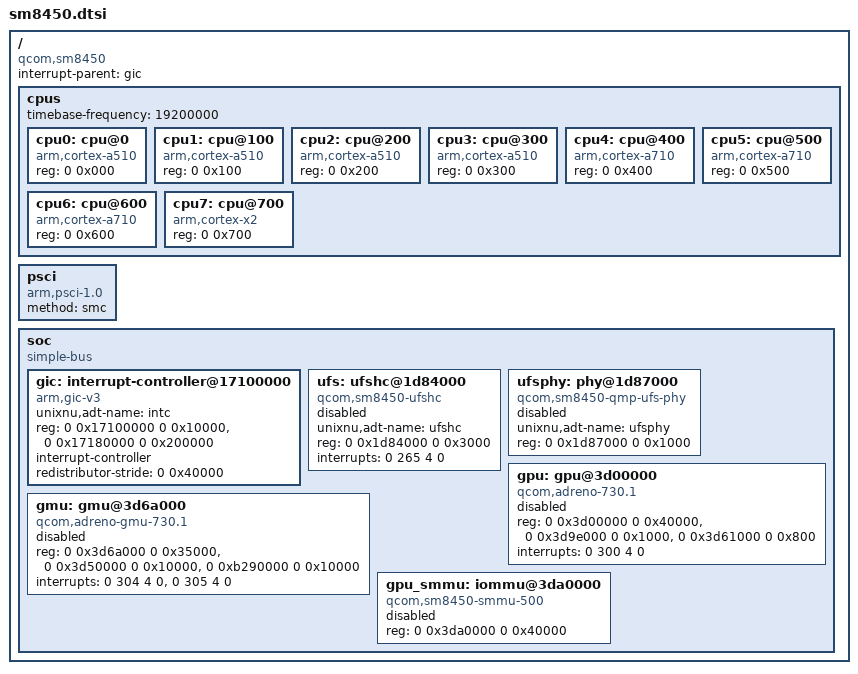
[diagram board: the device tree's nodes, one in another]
// SPDX-License-Identifier: BSD-3-Clause
// Qualcomm SM8450 / Snapdragon 8 Gen 1 (waipio).
//
// Register windows, interrupt numbers and CPU MPIDR values are transcribed from
// the mainline Linux device tree:
//   arch/arm64/boot/dts/qcom/sm8450.dtsi
//   torvalds/linux f1586048fb1dabb91c82fbe11557e505587973d3
//
// Only the resources UniXNU stage 0 consumes are modelled. The board DTS enables
// what it uses and adds memory, reserved regions and peripheral wiring.
/ {
    compatible = "qcom,sm8450";
    #address-cells = <2>;
    #size-cells = <2>;
    interrupt-parent = <&gic>;

    cpus {
        #address-cells = <2>;
        #size-cells = <0>;
        // XO / architected timer frequency: 19.2 MHz.
        timebase-frequency = <19200000>;

        // 4x Cortex-A510 (little), 3x Cortex-A710 (big), 1x Cortex-X2 (prime).
        // Qualcomm numbers cores in MPIDR Affinity1: 0x000 .. 0x700.
        cpu0: cpu@0 { device_type = "cpu"; compatible = "arm,cortex-a510"; reg = <0 0x000>; };
        cpu1: cpu@100 { device_type = "cpu"; compatible = "arm,cortex-a510"; reg = <0 0x100>; };
        cpu2: cpu@200 { device_type = "cpu"; compatible = "arm,cortex-a510"; reg = <0 0x200>; };
        cpu3: cpu@300 { device_type = "cpu"; compatible = "arm,cortex-a510"; reg = <0 0x300>; };
        cpu4: cpu@400 { device_type = "cpu"; compatible = "arm,cortex-a710"; reg = <0 0x400>; };
        cpu5: cpu@500 { device_type = "cpu"; compatible = "arm,cortex-a710"; reg = <0 0x500>; };
        cpu6: cpu@600 { device_type = "cpu"; compatible = "arm,cortex-a710"; reg = <0 0x600>; };
        cpu7: cpu@700 { device_type = "cpu"; compatible = "arm,cortex-x2"; reg = <0 0x700>; };
    };

    psci {
        compatible = "arm,psci-1.0";
        method = "smc";
    };

    soc {
        compatible = "simple-bus";
        #address-cells = <2>;
        #size-cells = <2>;
        ranges;

        gic: interrupt-controller@17100000 {
            compatible = "arm,gic-v3";
            unixnu,adt-name = "intc";
            reg = <0 0x17100000 0 0x10000>,      /* GICD */
                  <0 0x17180000 0 0x200000>;     /* GICR * 8 */
            #interrupt-cells = <4>;
            #address-cells = <0>;
            interrupt-controller;
            redistributor-stride = <0 0x40000>;
        };

        ufs: ufshc@1d84000 {
            compatible = "qcom,sm8450-ufshc";
            unixnu,adt-name = "ufshc";
            reg = <0 0x1d84000 0 0x3000>;
            interrupts = <0 265 4 0>;
            status = "disabled";
        };

        ufsphy: phy@1d87000 {
            compatible = "qcom,sm8450-qmp-ufs-phy";
            unixnu,adt-name = "ufsphy";
            reg = <0 0x1d87000 0 0x1000>;
            status = "disabled";
        };

        gpu: gpu@3d00000 {
            compatible = "qcom,adreno-730.1", "qcom,adreno";
            reg = <0 0x3d00000 0 0x40000>,
                  <0 0x3d9e000 0 0x1000>,
                  <0 0x3d61000 0 0x800>;
            reg-names = "kgsl_3d0_reg_memory", "cx_mem", "cx_dbgc";
            interrupts = <0 300 4 0>;
            status = "disabled";
        };

        gmu: gmu@3d6a000 {
            compatible = "qcom,adreno-gmu-730.1", "qcom,adreno-gmu";
            reg = <0 0x3d6a000 0 0x35000>,
                  <0 0x3d50000 0 0x10000>,
                  <0 0xb290000 0 0x10000>;
            reg-names = "gmu", "rscc", "gmu_pdc";
            interrupts = <0 304 4 0>, <0 305 4 0>;
            interrupt-names = "hfi", "gmu";
            status = "disabled";
        };

        gpu_smmu: iommu@3da0000 {
            compatible = "qcom,sm8450-smmu-500", "qcom,adreno-smmu", "qcom,smmu-500", "arm,mmu-500";
            reg = <0 0x3da0000 0 0x40000>;
            #iommu-cells = <2>;
            status = "disabled";
        };
    };
};
